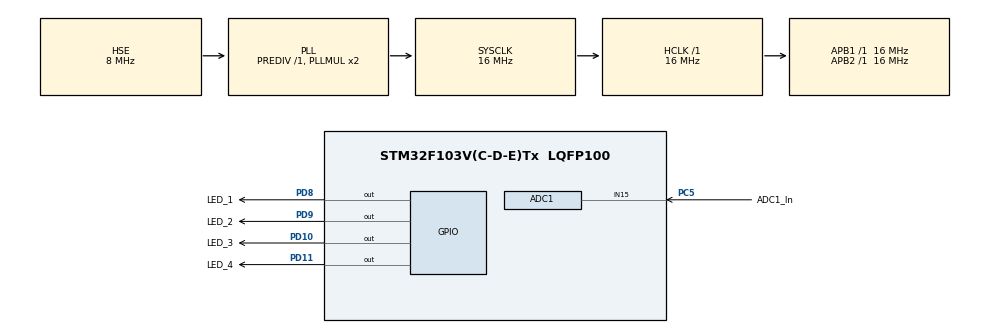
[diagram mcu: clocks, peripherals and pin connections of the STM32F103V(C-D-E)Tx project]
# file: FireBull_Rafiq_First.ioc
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ADC1.Channel-0\#ChannelRegularConversion=ADC_CHANNEL_15
ADC1.ContinuousConvMode=ENABLE
ADC1.NbrOfConversion=1
ADC1.NbrOfConversionFlag=1
ADC1.Rank-0\#ChannelRegularConversion=1
ADC1.SamplingTime-0\#ChannelRegularConversion=ADC_SAMPLETIME_1CYCLE_5
ADC1.master=1
Mcu.Family=STM32F1
Mcu.Name=STM32F103V(C-D-E)Tx
Mcu.Package=LQFP100
NVIC.PriorityGroup=NVIC_PRIORITYGROUP_4
NVIC.RCC_IRQn=true\:0\:0\:false\:false\:true\:true
OSC_IN.Mode=HSE-External-Oscillator
OSC_IN.Signal=RCC_OSC_IN
OSC_OUT.Mode=HSE-External-Oscillator
OSC_OUT.Signal=RCC_OSC_OUT
PA13.Mode=Serial_Wire
PA13.Signal=SYS_JTMS-SWDIO
PA14.Mode=Serial_Wire
PA14.Signal=SYS_JTCK-SWCLK
PC5.GPIO_Label=ADC1_In
PC5.Signal=ADCx_IN15
PD10.GPIO_Label=LED_3
PD10.GPIO_Speed=GPIO_SPEED_FREQ_HIGH
PD10.Signal=GPIO_Output
PD11.GPIO_Label=LED_4
PD11.GPIO_Speed=GPIO_SPEED_FREQ_HIGH
PD11.Signal=GPIO_Output
PD8.GPIO_Label=LED_1
PD8.GPIO_Speed=GPIO_SPEED_FREQ_HIGH
PD8.Signal=GPIO_Output
PD9.GPIO_Label=LED_2
PD9.GPIO_Speed=GPIO_SPEED_FREQ_HIGH
PD9.Signal=GPIO_Output
ProjectManager.HeapSize=0x200
ProjectManager.StackSize=0x400
ProjectManager.TargetToolchain=MDK-ARM V5
RCC.AHBFreq_Value=16000000
RCC.APB1Freq_Value=16000000
RCC.APB1TimFreq_Value=16000000
RCC.APB2Freq_Value=16000000
RCC.APB2TimFreq_Value=16000000
RCC.HCLKFreq_Value=16000000
RCC.PLLSourceVirtual=RCC_PLLSOURCE_HSE
RCC.SYSCLKFreq_VALUE=16000000
RCC.SYSCLKSource=RCC_SYSCLKSOURCE_PLLCLK
RCC.USBFreq_Value=16000000
SH.ADCx_IN15.0=ADC1_IN15,IN15
board=FireBull_Rafiq_First

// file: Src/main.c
/**
  ******************************************************************************
  * File Name          : main.c
  * Description        : Main program body
  ******************************************************************************
  ** This notice applies to any and all portions of this file
  * that are not between comment pairs USER CODE BEGIN and
  * USER CODE END. Other portions of this file, whether
  * inserted by the user or by software development tools
  * are owned by their respective copyright owners.
  *
  * COPYRIGHT(c) 2017 STMicroelectronics
  *
  * Redistribution and use in source and binary forms, with or without modification,
  * are permitted provided that the following conditions are met:
  *   1. Redistributions of source code must retain the above copyright notice,
  *      this list of conditions and the following disclaimer.
  *   2. Redistributions in binary form must reproduce the above copyright notice,
  *      this list of conditions and the following disclaimer in the documentation
  *      and/or other materials provided with the distribution.
  *   3. Neither the name of STMicroelectronics nor the names of its contributors
  *      may be used to endorse or promote products derived from this software
  *      without specific prior written permission.
  *
  * THIS SOFTWARE IS PROVIDED BY THE COPYRIGHT HOLDERS AND CONTRIBUTORS "AS IS"
  * AND ANY EXPRESS OR IMPLIED WARRANTIES, INCLUDING, BUT NOT LIMITED TO, THE
  * IMPLIED WARRANTIES OF MERCHANTABILITY AND FITNESS FOR A PARTICULAR PURPOSE ARE
  * DISCLAIMED. IN NO EVENT SHALL THE COPYRIGHT HOLDER OR CONTRIBUTORS BE LIABLE
  * FOR ANY DIRECT, INDIRECT, INCIDENTAL, SPECIAL, EXEMPLARY, OR CONSEQUENTIAL
  * DAMAGES (INCLUDING, BUT NOT LIMITED TO, PROCUREMENT OF SUBSTITUTE GOODS OR
  * SERVICES; LOSS OF USE, DATA, OR PROFITS; OR BUSINESS INTERRUPTION) HOWEVER
  * CAUSED AND ON ANY THEORY OF LIABILITY, WHETHER IN CONTRACT, STRICT LIABILITY,
  * OR TORT (INCLUDING NEGLIGENCE OR OTHERWISE) ARISING IN ANY WAY OUT OF THE USE
  * OF THIS SOFTWARE, EVEN IF ADVISED OF THE POSSIBILITY OF SUCH DAMAGE.
  *
  ******************************************************************************
  */

#include "main.h"
#include "stm32f1xx_hal.h"
#include "Rafiq_ILI9325_TFT.h"

ADC_HandleTypeDef hadc1;

/* USER CODE BEGIN PV */
/* Private variables ---------------------------------------------------------*/
uint16_t ADC_Raw;
const float Volt_Conv_Fact = (3.3 / 4095.0);
float ADC_Volt;
/* USER CODE END PV */

void SystemClock_Config(void);
static void MX_GPIO_Init(void);
static void MX_ADC1_Init(void);

/* USER CODE BEGIN PFP */
/* Private function prototypes -----------------------------------------------*/

/* USER CODE END PFP */

int main(void)
{

  /* MCU Configuration----------------------------------------------------------*/

  /* Reset of all peripherals, Initializes the Flash interface and the Systick. */
  HAL_Init();

  /* Configure the system clock */
  SystemClock_Config();

  /* Initialize all configured peripherals */
  MX_GPIO_Init();
  MX_ADC1_Init();

  /* USER CODE BEGIN 2 */

	HAL_ADC_Start(&hadc1);
	LCD_Init();

  /* USER CODE END 2 */

  /* Infinite loop */
  while (1)
  {

  /* USER CODE BEGIN 3 */
		HAL_GPIO_TogglePin(LED_1_GPIO_Port,LED_1_Pin);
		ADC_Raw = HAL_ADC_GetValue(&hadc1);
		ADC_Volt = ADC_Raw * Volt_Conv_Fact;
		HAL_Delay(500);
  }
  /* USER CODE END 3 */

}

/** System Clock Configuration
*/
void SystemClock_Config(void)
{

  RCC_OscInitTypeDef RCC_OscInitStruct;
  RCC_ClkInitTypeDef RCC_ClkInitStruct;
  RCC_PeriphCLKInitTypeDef PeriphClkInit;

    /**Initializes the CPU, AHB and APB busses clocks
    */
  RCC_OscInitStruct.OscillatorType = RCC_OSCILLATORTYPE_HSE;
  RCC_OscInitStruct.HSEState = RCC_HSE_ON;
  RCC_OscInitStruct.HSEPredivValue = RCC_HSE_PREDIV_DIV1;
  RCC_OscInitStruct.HSIState = RCC_HSI_ON;
  RCC_OscInitStruct.PLL.PLLState = RCC_PLL_ON;
  RCC_OscInitStruct.PLL.PLLSource = RCC_PLLSOURCE_HSE;
  RCC_OscInitStruct.PLL.PLLMUL = RCC_PLL_MUL2;
  if (HAL_RCC_OscConfig(&RCC_OscInitStruct) != HAL_OK)
  {
    _Error_Handler(__FILE__, __LINE__);
  }

    /**Initializes the CPU, AHB and APB busses clocks
    */
  RCC_ClkInitStruct.ClockType = RCC_CLOCKTYPE_HCLK|RCC_CLOCKTYPE_SYSCLK
                              |RCC_CLOCKTYPE_PCLK1|RCC_CLOCKTYPE_PCLK2;
  RCC_ClkInitStruct.SYSCLKSource = RCC_SYSCLKSOURCE_PLLCLK;
  RCC_ClkInitStruct.AHBCLKDivider = RCC_SYSCLK_DIV1;
  RCC_ClkInitStruct.APB1CLKDivider = RCC_HCLK_DIV1;
  RCC_ClkInitStruct.APB2CLKDivider = RCC_HCLK_DIV1;

  if (HAL_RCC_ClockConfig(&RCC_ClkInitStruct, FLASH_LATENCY_0) != HAL_OK)
  {
    _Error_Handler(__FILE__, __LINE__);
  }

  PeriphClkInit.PeriphClockSelection = RCC_PERIPHCLK_ADC;
  PeriphClkInit.AdcClockSelection = RCC_ADCPCLK2_DIV2;
  if (HAL_RCCEx_PeriphCLKConfig(&PeriphClkInit) != HAL_OK)
  {
    _Error_Handler(__FILE__, __LINE__);
  }

    /**Configure the Systick interrupt time
    */
  HAL_SYSTICK_Config(HAL_RCC_GetHCLKFreq()/1000);

    /**Configure the Systick
    */
  HAL_SYSTICK_CLKSourceConfig(SYSTICK_CLKSOURCE_HCLK);

  /* SysTick_IRQn interrupt configuration */
  HAL_NVIC_SetPriority(SysTick_IRQn, 0, 0);
}

/* ADC1 init function */
static void MX_ADC1_Init(void)
{

  ADC_ChannelConfTypeDef sConfig;

    /**Common config
    */
  hadc1.Instance = ADC1;
  hadc1.Init.ScanConvMode = ADC_SCAN_DISABLE;
  hadc1.Init.ContinuousConvMode = ENABLE;
  hadc1.Init.DiscontinuousConvMode = DISABLE;
  hadc1.Init.ExternalTrigConv = ADC_SOFTWARE_START;
  hadc1.Init.DataAlign = ADC_DATAALIGN_RIGHT;
  hadc1.Init.NbrOfConversion = 1;
  if (HAL_ADC_Init(&hadc1) != HAL_OK)
  {
    _Error_Handler(__FILE__, __LINE__);
  }

    /**Configure Regular Channel
    */
  sConfig.Channel = ADC_CHANNEL_15;
  sConfig.Rank = 1;
  sConfig.SamplingTime = ADC_SAMPLETIME_1CYCLE_5;
  if (HAL_ADC_ConfigChannel(&hadc1, &sConfig) != HAL_OK)
  {
    _Error_Handler(__FILE__, __LINE__);
  }

}

/** Configure pins as
        * Analog
        * Input
        * Output
        * EVENT_OUT
        * EXTI
*/
static void MX_GPIO_Init(void)
{

  GPIO_InitTypeDef GPIO_InitStruct;

  /* GPIO Ports Clock Enable */
  __HAL_RCC_GPIOC_CLK_ENABLE();
  __HAL_RCC_GPIOD_CLK_ENABLE();
  __HAL_RCC_GPIOA_CLK_ENABLE();

  /*Configure GPIO pin Output Level */
  HAL_GPIO_WritePin(GPIOD, LED_1_Pin|LED_2_Pin|LED_3_Pin|LED_4_Pin, GPIO_PIN_RESET);

  /*Configure GPIO pins : LED_1_Pin LED_2_Pin LED_3_Pin LED_4_Pin */
  GPIO_InitStruct.Pin = LED_1_Pin|LED_2_Pin|LED_3_Pin|LED_4_Pin;
  GPIO_InitStruct.Mode = GPIO_MODE_OUTPUT_PP;
  GPIO_InitStruct.Speed = GPIO_SPEED_FREQ_HIGH;
  HAL_GPIO_Init(GPIOD, &GPIO_InitStruct);

}

void _Error_Handler(char * file, int line)
{
  while(1)
  {
  }
}

/************************ (C) COPYRIGHT STMicroelectronics *****END OF FILE****/
